AUTOSAR XML (schema 00046)
package /ComponentTypes
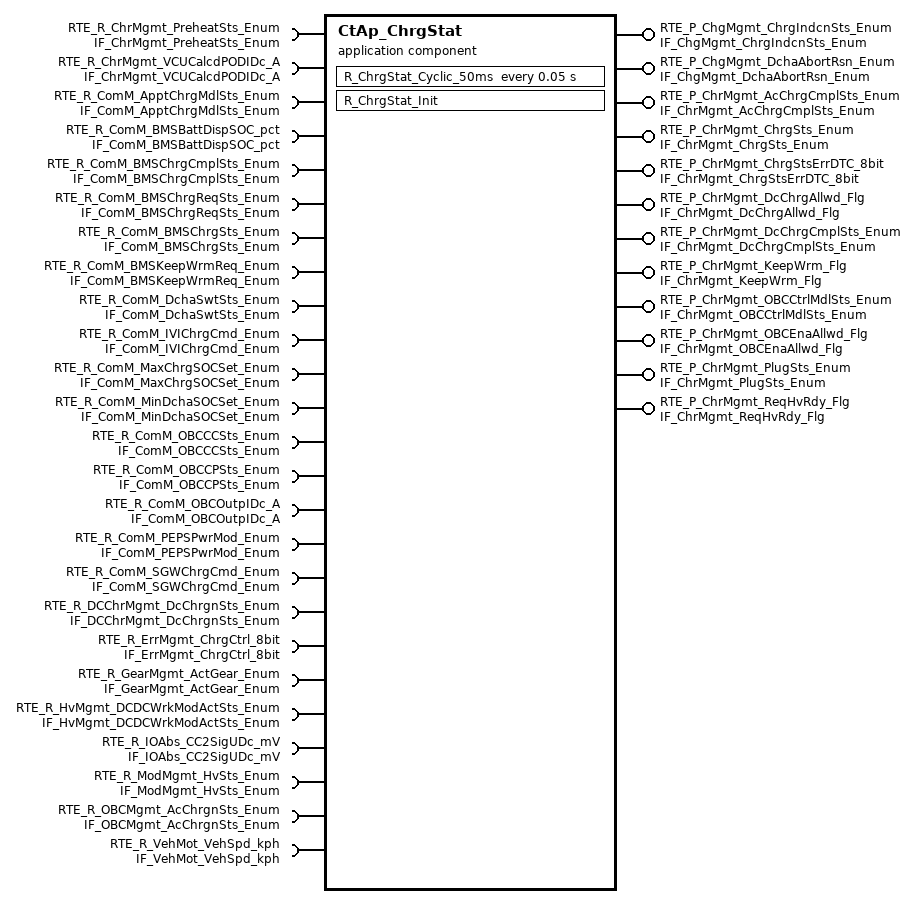
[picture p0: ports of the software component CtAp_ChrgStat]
  application sw component type CtAp_ChrgStat
    12 x provide port:
      RTE_P_ChgMgmt_ChrgIndcnSts_Enum: nonqueued-sender-com-spec{data-element=tec_ChgMgmt_ChrgIndcnSts_Enum, init-value=0}, provided-interface=IF_ChgMgmt_ChrgIndcnSts_Enum
      RTE_P_ChgMgmt_DchaAbortRsn_Enum: nonqueued-sender-com-spec{data-element=tec_ChgMgmt_DchaAbortRsn_Enum, init-value=0}, provided-interface=IF_ChgMgmt_DchaAbortRsn_Enum
      RTE_P_ChrMgmt_AcChrgCmplSts_Enum: nonqueued-sender-com-spec{data-element=tec_ChrMgmt_AcChrgCmplSts_Enum, init-value=0}, provided-interface=IF_ChrMgmt_AcChrgCmplSts_Enum
      RTE_P_ChrMgmt_ChrgSts_Enum: nonqueued-sender-com-spec{data-element=tec_ChrMgmt_ChrgSts_Enum, init-value=0}, provided-interface=IF_ChrMgmt_ChrgSts_Enum
      RTE_P_ChrMgmt_ChrgStsErrDTC_8bit: nonqueued-sender-com-spec{data-element=tec_ChrMgmt_ChrgStsErrDTC_8bit, init-value=0}, provided-interface=IF_ChrMgmt_ChrgStsErrDTC_8bit
      RTE_P_ChrMgmt_DcChrgAllwd_Flg: nonqueued-sender-com-spec{data-element=tec_ChrMgmt_DcChrgAllwd_Flg, init-value=0}, provided-interface=IF_ChrMgmt_DcChrgAllwd_Flg
      RTE_P_ChrMgmt_DcChrgCmplSts_Enum: nonqueued-sender-com-spec{data-element=tec_ChrMgmt_DcChrgCmplSts_Enum, init-value=0}, provided-interface=IF_ChrMgmt_DcChrgCmplSts_Enum
      RTE_P_ChrMgmt_KeepWrm_Flg: nonqueued-sender-com-spec{data-element=tec_ChrMgmt_KeepWrm_Flg, init-value=0}, provided-interface=IF_ChrMgmt_KeepWrm_Flg
      RTE_P_ChrMgmt_OBCCtrlMdlSts_Enum: nonqueued-sender-com-spec{data-element=tec_ChrMgmt_OBCCtrlMdlSts_Enum, init-value=0}, provided-interface=IF_ChrMgmt_OBCCtrlMdlSts_Enum
      RTE_P_ChrMgmt_OBCEnaAllwd_Flg: nonqueued-sender-com-spec{data-element=tec_ChrMgmt_OBCEnaAllwd_Flg, init-value=0}, provided-interface=IF_ChrMgmt_OBCEnaAllwd_Flg
      RTE_P_ChrMgmt_PlugSts_Enum: nonqueued-sender-com-spec{data-element=tec_ChrMgmt_PlugSts_Enum, init-value=0}, provided-interface=IF_ChrMgmt_PlugSts_Enum
      RTE_P_ChrMgmt_ReqHvRdy_Flg: nonqueued-sender-com-spec{data-element=tec_ChrMgmt_ReqHvRdy_Flg, init-value=0}, provided-interface=IF_ChrMgmt_ReqHvRdy_Flg
    25 x require port:
      RTE_R_ChrMgmt_PreheatSts_Enum: nonqueued-receiver-com-spec{data-element=tec_ChrMgmt_PreheatSts_Enum, filter=data-filter-type=ALWAYS, init-value=0}, required-interface=IF_ChrMgmt_PreheatSts_Enum
      RTE_R_ChrMgmt_VCUCalcdPODIDc_A: nonqueued-receiver-com-spec{data-element=tec_ChrMgmt_VCUCalcdPODIDc_A, filter=data-filter-type=ALWAYS, init-value=0}, required-interface=IF_ChrMgmt_VCUCalcdPODIDc_A
      RTE_R_ComM_ApptChrgMdlSts_Enum: nonqueued-receiver-com-spec{data-element=tec_ComM_ApptChrgMdlSts_Enum, filter=data-filter-type=ALWAYS, init-value=0}, required-interface=IF_ComM_ApptChrgMdlSts_Enum
      RTE_R_ComM_BMSBattDispSOC_pct: nonqueued-receiver-com-spec{data-element=tec_ComM_BMSBattDispSOC_pct, filter=data-filter-type=ALWAYS, init-value=0}, required-interface=IF_ComM_BMSBattDispSOC_pct
      RTE_R_ComM_BMSChrgCmplSts_Enum: nonqueued-receiver-com-spec{data-element=tec_ComM_BMSChrgCmplSts_Enum, filter=data-filter-type=ALWAYS, init-value=0}, required-interface=IF_ComM_BMSChrgCmplSts_Enum
      RTE_R_ComM_BMSChrgReqSts_Enum: nonqueued-receiver-com-spec{data-element=tec_ComM_BMSChrgReqSts_Enum, filter=data-filter-type=ALWAYS, init-value=0}, required-interface=IF_ComM_BMSChrgReqSts_Enum
      RTE_R_ComM_BMSChrgSts_Enum: nonqueued-receiver-com-spec{data-element=tec_ComM_BMSChrgSts_Enum, filter=data-filter-type=ALWAYS, init-value=0}, required-interface=IF_ComM_BMSChrgSts_Enum
      RTE_R_ComM_BMSKeepWrmReq_Enum: nonqueued-receiver-com-spec{data-element=tec_ComM_BMSKeepWrmReq_Enum, filter=data-filter-type=ALWAYS, init-value=0}, required-interface=IF_ComM_BMSKeepWrmReq_Enum
      RTE_R_ComM_DchaSwtSts_Enum: nonqueued-receiver-com-spec{data-element=tec_ComM_DchaSwtSts_Enum, filter=data-filter-type=ALWAYS, init-value=0}, required-interface=IF_ComM_DchaSwtSts_Enum
      RTE_R_ComM_IVIChrgCmd_Enum: nonqueued-receiver-com-spec{data-element=tec_ComM_IVIChrgCmd_Enum, filter=data-filter-type=ALWAYS, init-value=0}, required-interface=IF_ComM_IVIChrgCmd_Enum
      RTE_R_ComM_MaxChrgSOCSet_Enum: nonqueued-receiver-com-spec{data-element=tec_ComM_MaxChrgSOCSet_Enum, filter=data-filter-type=ALWAYS}, required-interface=IF_ComM_MaxChrgSOCSet_Enum
      RTE_R_ComM_MinDchaSOCSet_Enum: nonqueued-receiver-com-spec{data-element=tec_ComM_MinDchaSOCSet_Enum, filter=data-filter-type=ALWAYS, init-value=0}, required-interface=IF_ComM_MinDchaSOCSet_Enum
      RTE_R_ComM_OBCCCSts_Enum: nonqueued-receiver-com-spec{data-element=tec_ComM_OBCCCSts_Enum, filter=data-filter-type=ALWAYS, init-value=0}, required-interface=IF_ComM_OBCCCSts_Enum
      RTE_R_ComM_OBCCPSts_Enum: nonqueued-receiver-com-spec{data-element=tec_ComM_OBCCPSts_Enum, filter=data-filter-type=ALWAYS, init-value=0}, required-interface=IF_ComM_OBCCPSts_Enum
      RTE_R_ComM_OBCOutpIDc_A: nonqueued-receiver-com-spec{data-element=tec_ComM_OBCOutpIDc_A, filter=data-filter-type=ALWAYS, init-value=0}, required-interface=IF_ComM_OBCOutpIDc_A
      RTE_R_ComM_PEPSPwrMod_Enum: nonqueued-receiver-com-spec{data-element=tec_ComM_PEPSPwrMod_Enum, filter=data-filter-type=ALWAYS, init-value=0}, required-interface=IF_ComM_PEPSPwrMod_Enum
      RTE_R_ComM_SGWChrgCmd_Enum: nonqueued-receiver-com-spec{data-element=tec_ComM_SGWChrgCmd_Enum, filter=data-filter-type=ALWAYS, init-value=0}, required-interface=IF_ComM_SGWChrgCmd_Enum
      RTE_R_DCChrMgmt_DcChrgnSts_Enum: nonqueued-receiver-com-spec{data-element=tec_DCChrMgmt_DcChrgnSts_Enum, filter=data-filter-type=ALWAYS, init-value=0}, required-interface=IF_DCChrMgmt_DcChrgnSts_Enum
      RTE_R_ErrMgmt_ChrgCtrl_8bit: nonqueued-receiver-com-spec{data-element=tec_ErrMgmt_ChrgCtrl_8bit, filter=data-filter-type=ALWAYS, init-value=0}, required-interface=IF_ErrMgmt_ChrgCtrl_8bit
      RTE_R_GearMgmt_ActGear_Enum: nonqueued-receiver-com-spec{data-element=tec_GearMgmt_ActGear_Enum, filter=data-filter-type=ALWAYS, init-value=0}, required-interface=IF_GearMgmt_ActGear_Enum
      RTE_R_HvMgmt_DCDCWrkModActSts_Enum: nonqueued-receiver-com-spec{data-element=tec_HvMgmt_DCDCWrkModActSts_Enum, filter=data-filter-type=ALWAYS, init-value=0}, required-interface=IF_HvMgmt_DCDCWrkModActSts_Enum
      RTE_R_IOAbs_CC2SigUDc_mV: nonqueued-receiver-com-spec{data-element=tec_IOAbs_CC2SigUDc_mV, filter=data-filter-type=ALWAYS, init-value=0}, required-interface=IF_IOAbs_CC2SigUDc_mV
      RTE_R_ModMgmt_HvSts_Enum: nonqueued-receiver-com-spec{data-element=tec_ModMgmt_HvSts_Enum, filter=data-filter-type=ALWAYS, init-value=0}, required-interface=IF_ModMgmt_HvSts_Enum
      RTE_R_OBCMgmt_AcChrgnSts_Enum: nonqueued-receiver-com-spec{data-element=tec_OBCMgmt_AcChrgnSts_Enum, filter=data-filter-type=ALWAYS, init-value=0}, required-interface=IF_OBCMgmt_AcChrgnSts_Enum
      RTE_R_VehMot_VehSpd_kph: nonqueued-receiver-com-spec{data-element=tec_VehMot_VehSpd_kph, filter=data-filter-type=ALWAYS, init-value=0}, required-interface=IF_VehMot_VehSpd_kph
    behavior CtAp_ChrgStat_InternalBehavior
      timing event TMT_R_ChrgStat_Cyclic_50ms: start-on-event=R_ChrgStat_Cyclic_50ms, period=0.05
      init event CtAp_ChrgStat_InitEvent: start-on-event=R_ChrgStat_Init
      runnable R_ChrgStat_Cyclic_50ms
        data-receive-point-by-arguments:
          25 x access:
            REC_RTE_R_ChrMgmt_PreheatSts_Enum_tec_ChrMgmt_PreheatSts_Enum: accessed-variable=RTE_R_ChrMgmt_PreheatSts_Enum.tec_ChrMgmt_PreheatSts_Enum
            REC_RTE_R_ChrMgmt_VCUCalcdPODIDc_A_tec_ChrMgmt_VCUCalcdPODIDc_A: accessed-variable=RTE_R_ChrMgmt_VCUCalcdPODIDc_A.tec_ChrMgmt_VCUCalcdPODIDc_A
            REC_RTE_R_ComM_ApptChrgMdlSts_Enum_tec_ComM_ApptChrgMdlSts_Enum: accessed-variable=RTE_R_ComM_ApptChrgMdlSts_Enum.tec_ComM_ApptChrgMdlSts_Enum
            REC_RTE_R_ComM_BMSBattDispSOC_pct_tec_ComM_BMSBattDispSOC_pct: accessed-variable=RTE_R_ComM_BMSBattDispSOC_pct.tec_ComM_BMSBattDispSOC_pct
            REC_RTE_R_ComM_BMSChrgCmplSts_Enum_tec_ComM_BMSChrgCmplSts_Enum: accessed-variable=RTE_R_ComM_BMSChrgCmplSts_Enum.tec_ComM_BMSChrgCmplSts_Enum
            REC_RTE_R_ComM_BMSChrgReqSts_Enum_tec_ComM_BMSChrgReqSts_Enum: accessed-variable=RTE_R_ComM_BMSChrgReqSts_Enum.tec_ComM_BMSChrgReqSts_Enum
            REC_RTE_R_ComM_BMSChrgSts_Enum_tec_ComM_BMSChrgSts_Enum: accessed-variable=RTE_R_ComM_BMSChrgSts_Enum.tec_ComM_BMSChrgSts_Enum
            REC_RTE_R_ComM_BMSKeepWrmReq_Enum_tec_ComM_BMSKeepWrmReq_Enum: accessed-variable=RTE_R_ComM_BMSKeepWrmReq_Enum.tec_ComM_BMSKeepWrmReq_Enum
            REC_RTE_R_ComM_DchaSwtSts_Enum_tec_ComM_DchaSwtSts_Enum: accessed-variable=RTE_R_ComM_DchaSwtSts_Enum.tec_ComM_DchaSwtSts_Enum
            REC_RTE_R_ComM_IVIChrgCmd_Enum_tec_ComM_IVIChrgCmd_Enum: accessed-variable=RTE_R_ComM_IVIChrgCmd_Enum.tec_ComM_IVIChrgCmd_Enum
            REC_RTE_R_ComM_MaxChrgSOCSet_enum_tec_ComM_MaxChrgSOCSet_enum: accessed-variable=RTE_R_ComM_MaxChrgSOCSet_Enum.tec_ComM_MaxChrgSOCSet_Enum
            REC_RTE_R_ComM_MinDchaSOCSet_Enum_tec_ComM_MinDchaSOCSet_Enum: accessed-variable=RTE_R_ComM_MinDchaSOCSet_Enum.tec_ComM_MinDchaSOCSet_Enum
            REC_RTE_R_ComM_OBCCCSts_Enum_tec_ComM_OBCCCSts_Enum: accessed-variable=RTE_R_ComM_OBCCCSts_Enum.tec_ComM_OBCCCSts_Enum
            REC_RTE_R_ComM_OBCCPSts_Enum_tec_ComM_OBCCPSts_Enum: accessed-variable=RTE_R_ComM_OBCCPSts_Enum.tec_ComM_OBCCPSts_Enum
            REC_RTE_R_ComM_OBCOutpIDc_A_tec_ComM_OBCOutpIDc_A: accessed-variable=RTE_R_ComM_OBCOutpIDc_A.tec_ComM_OBCOutpIDc_A
            REC_RTE_R_ComM_PEPSPwrMod_Enum_tec_ComM_PEPSPwrMod_Enum: accessed-variable=RTE_R_ComM_PEPSPwrMod_Enum.tec_ComM_PEPSPwrMod_Enum
            REC_RTE_R_ComM_SGWChrgCmd_Enum_tec_ComM_SGWChrgCmd_Enum: accessed-variable=RTE_R_ComM_SGWChrgCmd_Enum.tec_ComM_SGWChrgCmd_Enum
            REC_RTE_R_DCChrMgmt_DcChrgnSts_Enum_tec_DCChrMgmt_DcChrgnSts_Enum: accessed-variable=RTE_R_DCChrMgmt_DcChrgnSts_Enum.tec_DCChrMgmt_DcChrgnSts_Enum
            REC_RTE_R_ErrMgmt_ChrgCtrl_8bit_tec_ErrMgmt_ChrgCtrl_8bit: accessed-variable=RTE_R_ErrMgmt_ChrgCtrl_8bit.tec_ErrMgmt_ChrgCtrl_8bit
            REC_RTE_R_GearMgmt_ActGear_Enum_tec_GearMgmt_ActGear_Enum: accessed-variable=RTE_R_GearMgmt_ActGear_Enum.tec_GearMgmt_ActGear_Enum
            REC_RTE_R_HvMgmt_DCDCWrkModActSts_Enum_tec_HvMgmt_DCDCWrkModActSts_Enum: accessed-variable=RTE_R_HvMgmt_DCDCWrkModActSts_Enum.tec_HvMgmt_DCDCWrkModActSts_Enum
            REC_RTE_R_IOAbs_CC2SigUDc_mV_tec_IOAbs_CC2SigUDc_mV: accessed-variable=RTE_R_IOAbs_CC2SigUDc_mV.tec_IOAbs_CC2SigUDc_mV
            REC_RTE_R_ModMgmt_HvSts_Enum_tec_ModMgmt_HvSts_Enum: accessed-variable=RTE_R_ModMgmt_HvSts_Enum.tec_ModMgmt_HvSts_Enum
            REC_RTE_R_OBCMgmt_AcChrgnSts_Enum_tec_OBCMgmt_AcChrgnSts_Enum: accessed-variable=RTE_R_OBCMgmt_AcChrgnSts_Enum.tec_OBCMgmt_AcChrgnSts_Enum
            REC_RTE_R_VehMot_VehSpd_kph_tec_VehMot_VehSpd_kph: accessed-variable=RTE_R_VehMot_VehSpd_kph.tec_VehMot_VehSpd_kph
        data-send-points:
          12 x access:
            SEND_RTE_P_ChgMgmt_ChrgIndcnSts_Enum_tec_ChgMgmt_ChrgIndcnSts_Enum: accessed-variable=RTE_P_ChgMgmt_ChrgIndcnSts_Enum.tec_ChgMgmt_ChrgIndcnSts_Enum
            SEND_RTE_P_ChgMgmt_DchaAbortRsn_Enum_tec_ChgMgmt_DchaAbortRsn_Enum: accessed-variable=RTE_P_ChgMgmt_DchaAbortRsn_Enum.tec_ChgMgmt_DchaAbortRsn_Enum
            SEND_RTE_P_ChrMgmt_AcChrgCmplSts_Enum_tec_ChrMgmt_AcChrgCmplSts_Enum: accessed-variable=RTE_P_ChrMgmt_AcChrgCmplSts_Enum.tec_ChrMgmt_AcChrgCmplSts_Enum
            SEND_RTE_P_ChrMgmt_ChrgSts_Enum_tec_ChrMgmt_ChrgSts_Enum: accessed-variable=RTE_P_ChrMgmt_ChrgSts_Enum.tec_ChrMgmt_ChrgSts_Enum
            SEND_RTE_P_ChrMgmt_ChrgStsErrDTC_8bit_tec_ChrMgmt_ChrgStsErrDTC_8bit: accessed-variable=RTE_P_ChrMgmt_ChrgStsErrDTC_8bit.tec_ChrMgmt_ChrgStsErrDTC_8bit
            SEND_RTE_P_ChrMgmt_DcChrgAllwd_Flg_tec_ChrMgmt_DcChrgAllwd_Flg: accessed-variable=RTE_P_ChrMgmt_DcChrgAllwd_Flg.tec_ChrMgmt_DcChrgAllwd_Flg
            SEND_RTE_P_ChrMgmt_DcChrgCmplSts_Enum_tec_ChrMgmt_DcChrgCmplSts_Enu: accessed-variable=RTE_P_ChrMgmt_DcChrgCmplSts_Enum.tec_ChrMgmt_DcChrgCmplSts_Enum
            SEND_RTE_P_ChrMgmt_KeepWrm_Flg_tec_ChrMgmt_KeepWrm_Flg: accessed-variable=RTE_P_ChrMgmt_KeepWrm_Flg.tec_ChrMgmt_KeepWrm_Flg
            SEND_RTE_P_ChrMgmt_OBCCtrlMdlSts_Enum_tec_ChrMgmt_OBCCtrlMdlSts_Enum: accessed-variable=RTE_P_ChrMgmt_OBCCtrlMdlSts_Enum.tec_ChrMgmt_OBCCtrlMdlSts_Enum
            SEND_RTE_P_ChrMgmt_OBCEnaAllwd_Flg_tec_ChrMgmt_OBCEnaAllwd_Flg: accessed-variable=RTE_P_ChrMgmt_OBCEnaAllwd_Flg.tec_ChrMgmt_OBCEnaAllwd_Flg
            SEND_RTE_P_ChrMgmt_PlugSts_Enum_tec_ChrMgmt_PlugSts_Enum: accessed-variable=RTE_P_ChrMgmt_PlugSts_Enum.tec_ChrMgmt_PlugSts_Enum
            SEND_RTE_P_ChrMgmt_ReqHvRdy_Flg_tec_ChrMgmt_ReqHvRdy_Flg: accessed-variable=RTE_P_ChrMgmt_ReqHvRdy_Flg.tec_ChrMgmt_ReqHvRdy_Flg
      runnable R_ChrgStat_Init
  swc implementation CtAp_ChrgStat_Implementation: behavior=CtAp_ChrgStat_InternalBehavior
    code-descriptors:
      code Default: artifact-descriptors=autosar-engineering-object={short-label=Default, category=SWOBJ}
